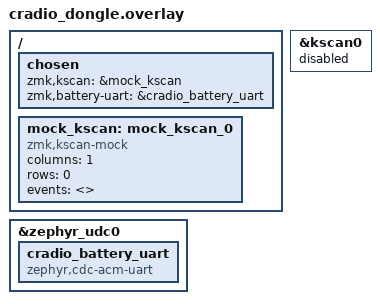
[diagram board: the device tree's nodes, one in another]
#include "cradio_dongle.dtsi"

/ {
    chosen {
        zmk,kscan = &mock_kscan;
        zmk,battery-uart = &cradio_battery_uart;
    };

    mock_kscan: mock_kscan_0 {
        compatible = "zmk,kscan-mock";
        columns = <1>;
        rows = <0>;
        events = <>;
    };
};

&zephyr_udc0 {
    cradio_battery_uart: cradio_battery_uart {
        compatible = "zephyr,cdc-acm-uart";
    };
};

&kscan0 {
    status = "disabled";
};
